# M037 register map
File version: 2.0.2.2
TOSHIBA Cortex-M3 MCU
Registers are 32-bit, read-write, reset 0x0 unless marked. A register's access mark holds for its fields unless they carry their own. Offsets are from the block's base; lines under a group give offsets from that group; [hi:lo] are bit positions; {n}, {i} and the like mark numbered series; 'fields as' and 'values as' point back to an identical list; <NAME> marks a mode.

## Memory map
0x40000000 DMAC blocks up to offset 0x134 — DMA Controller
0x4005F000 DMACRQ size 0x8 — DMAC Request Control
0x4008D000 T16A0 size 0x14 — 16-bit TimerA
0x4008E000 T16A1 size 0x14
0x400A0000 I2C size 0x1C
0x400C0000 PA blocks up to offset 0x3C — Port A
0x400C0100 PB blocks up to offset 0x3C — Port B
0x400C0200 PC blocks up to offset 0x3C — Poer C
0x400C0300 PD blocks up to offset 0x3C — Port D
0x400C0400 PE blocks up to offset 0x3C — Port E
0x400C0500 PF blocks up to offset 0x3C — Port F
0x400C0600 PG blocks up to offset 0x3C — Port G
0x400C4000 TB0 size 0x34 — 16-bit Timer_Event Counter (TB)
0x400C4100 TB1 size 0x34
0x400C4200 TB2 size 0x34
0x400C4300 TB3 size 0x34
0x400C4400 TB4 size 0x34
0x400C4500 TB5 size 0x34
0x400C4600 TB6 size 0x34
0x400C4700 TB7 size 0x34
0x400E1000 SC0 size 0x38 — SC
0x400E1100 SC1 size 0x38
0x400E1200 SC2 size 0x38
0x400E1300 SC3 size 0x38
0x400E1400 SC4 size 0x38
0x400F2000 WD size 0x8 — WDT
0x400F3000 CG blocks up to offset 0x6C
0x400F4000 LVD blocks up to offset 0x8
0x400FC000 AD blocks up to offset 0x6C — ADC
0x41FFF000 FC blocks up to offset 0x34

## DMAC — DMA Controller
Base 0x40000000
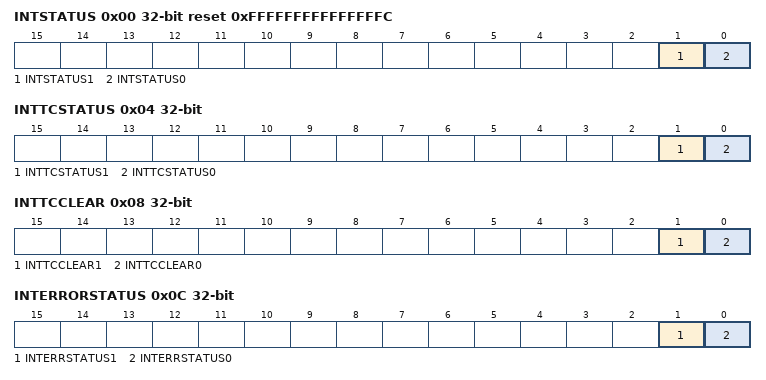
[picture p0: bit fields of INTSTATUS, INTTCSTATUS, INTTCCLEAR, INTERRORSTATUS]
0x00 INTSTATUS ro reset 0xFFFFFFFFFFFFFFFC — DMAC Interrupt status register
  [1] INTSTATUS1, [0] INTSTATUS0
0x04 INTTCSTATUS ro — DMAC Interrupt Terminal Count Status Register
  [1] INTTCSTATUS1, [0] INTTCSTATUS0
0x08 INTTCCLEAR wo — DMAC Interrupt Terminal Count Clear Register
  [1] INTTCCLEAR1, [0] INTTCCLEAR0
0x0C INTERRORSTATUS ro — DMAC Interrupt Error Status Register
  [1] INTERRSTATUS1, [0] INTERRSTATUS0
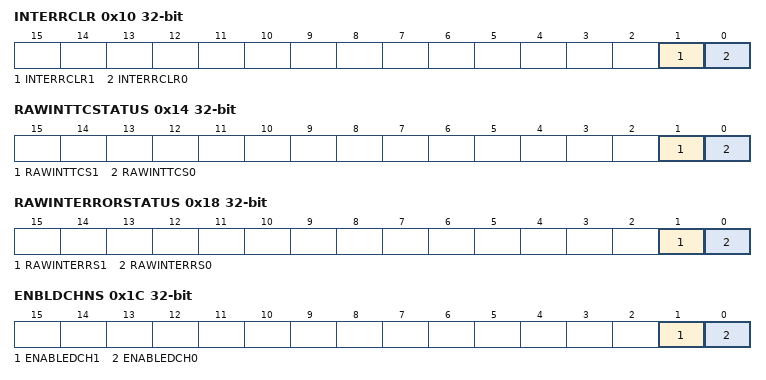
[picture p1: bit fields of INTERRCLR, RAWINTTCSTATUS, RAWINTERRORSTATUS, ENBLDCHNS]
0x10 INTERRCLR wo — DMAC Interrupt Error Clear Register
  [1] INTERRCLR1, [0] INTERRCLR0
0x14 RAWINTTCSTATUS ro — DMAC Raw Interrupt Terminal Count Status Register
  [1] RAWINTTCS1, [0] RAWINTTCS0
0x18 RAWINTERRORSTATUS ro — DMAC Raw Error Interrupt Status Register
  [1] RAWINTERRS1, [0] RAWINTERRS0
0x1C ENBLDCHNS ro — DMAC Enabled Channel Register
  [1] ENABLEDCH1, [0] ENABLEDCH0
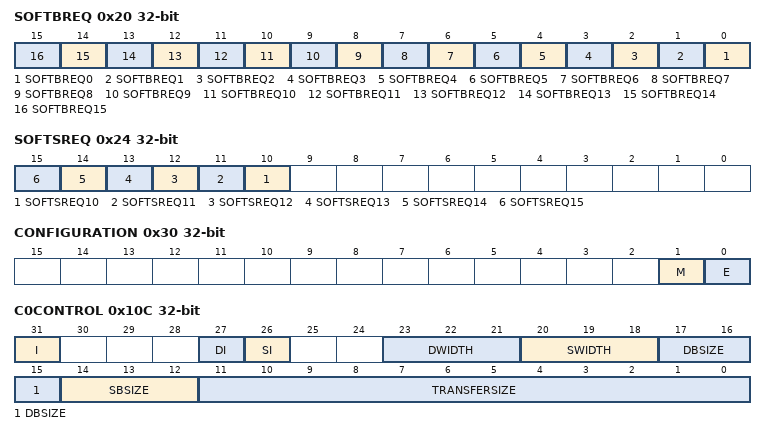
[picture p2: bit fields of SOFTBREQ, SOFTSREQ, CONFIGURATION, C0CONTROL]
0x20 SOFTBREQ — DMAC Software Burst Request Register
  [n] SOFTBREQ{n} (n=0..15)
0x24 SOFTSREQ — DMAC Software Single Request Register
  [n] SOFTSREQ{n} (n=10..15)
0x30 CONFIGURATION — DMAC Configuration Register
  [1] M, [0] E
0x100 C0SRCADDR — DMAC Channel0 Source Address Register
  [31:0] SRCADDR
0x104 C0DESTADDR — DMAC Channel0 Destination Address Register
  [31:0] DESTADDR
0x108 C0LLI — DMAC Channel0 Linked List Item Register
  [31:2] LLI
0x10C C0CONTROL — DMAC Channel0 Control Register
  [31] I, [27] DI, [26] SI, [23:21] DWIDTH, [20:18] SWIDTH, [17:15] DBSIZE, [14:12] SBSIZE, [11:0] TRANSFERSIZE
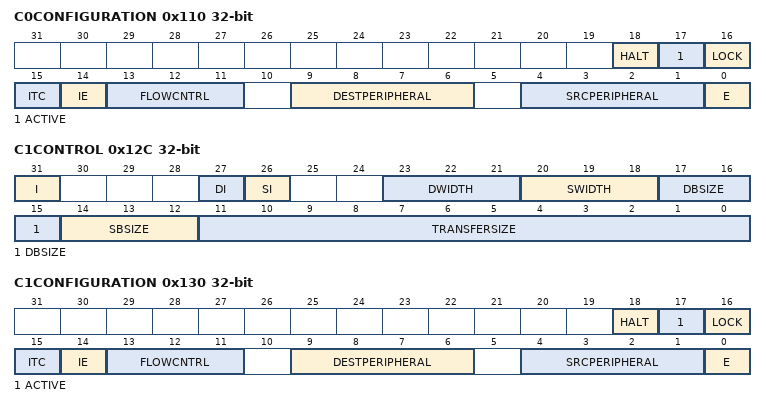
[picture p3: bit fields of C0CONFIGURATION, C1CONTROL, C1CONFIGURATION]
0x110 C0CONFIGURATION — DMAC Channel0 Configuration Register
  [18] HALT, [17] ACTIVE ro, [16] LOCK, [15] ITC, [14] IE, [13:11] FLOWCNTRL, [9:6] DESTPERIPHERAL, [4:1] SRCPERIPHERAL, [0] E
0x120 C1SRCADDR — DMAC Channel1 Source Address Register
  [31:0] SRCADDR
0x124 C1DESTADDR — DMAC Channel1 Destination Address Register
  [31:0] DESTADDR
0x128 C1LLI — DMAC Channel1 Linked List Item Register
  [31:1] LLI
0x12C C1CONTROL — DMAC Channel1 Control Register
  fields as C0CONTROL
0x130 C1CONFIGURATION — DMAC Channel1 Configuration Register
  fields as C0CONFIGURATION

## DMACRQ — DMAC Request Control
Base 0x4005F000
0x00 REDGE reset 0x14 — DMAC Request Edge setting Register
  [0] I2CDMAC
0x04 RCLR wo reset 0x14 — DMAC Request Clear Register
  [0] DCLR0

## T16A0 — 16-bit TimerA
Base 0x4008D000
Same registers: T16A1 0x4008E000
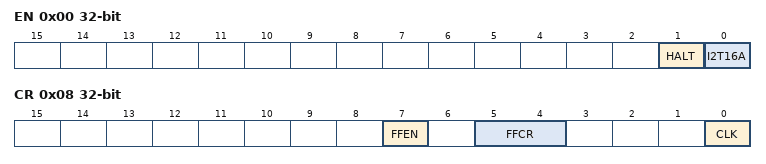
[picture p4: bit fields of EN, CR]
0x00 EN — Enable Register
  [1] HALT, [0] I2T16A
0x04 RUN
  [0] RUN
0x08 CR — Control Register
  [7] FFEN, [5:4] FFCR wo, [0] CLK
0x0C RG — Timer Register
  [15:0] RG
0x10 CP ro — Capture Register
  [15:0] CP
